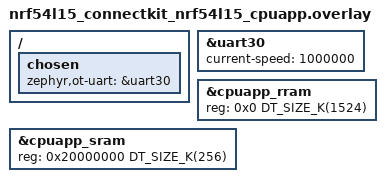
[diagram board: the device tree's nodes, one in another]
/* Copyright (c) 2024 Nordic Semiconductor ASA
 *
 * SPDX-License-Identifier: LicenseRef-Nordic-5-Clause
 */

&uart30 {
    current-speed = <1000000>;
    status = "okay";
};

 / {
    chosen {
        zephyr,ot-uart = &uart30;
    };
};

// restore full RRAM and SRAM space - by default some parts are dedicated to FLPR
&cpuapp_rram {
	reg = <0x0 DT_SIZE_K(1524)>;
};

&cpuapp_sram {
	reg = <0x20000000 DT_SIZE_K(256)>;
	ranges = <0x0 0x20000000  DT_SIZE_K(256)>;
};
